# RT58X register map
Series: ARMv8-M Mainline; File version: 1.0
CPU: CM3 r0p0, little endian, MPU, no FPU, VTOR, 3 interrupt priority bits
Registers are 32-bit, read-write, reset 0x0 unless marked. A register's access mark holds for its fields unless they carry their own. Offsets are from the block's base; [hi:lo] are bit positions; {n}, {i} and the like mark numbered series; 'fields as' and 'values as' point back to an identical list; <NAME> marks a mode.

## PWM — PWM Register block
Base 0xA0C00000
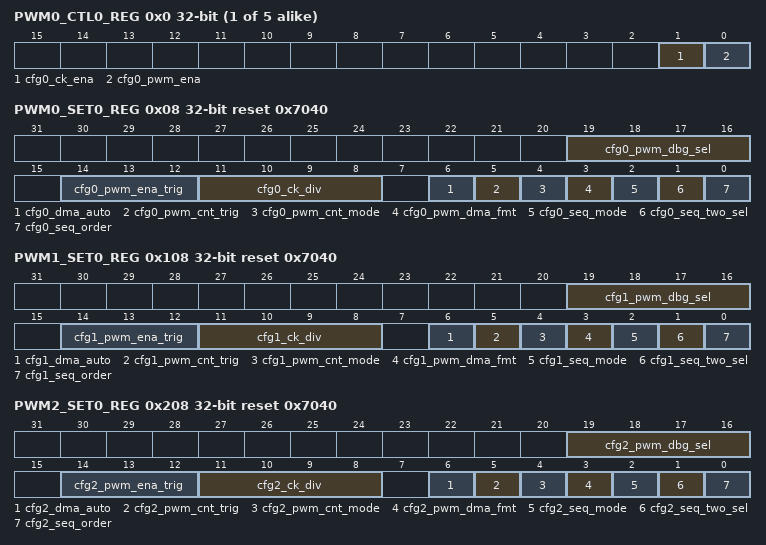
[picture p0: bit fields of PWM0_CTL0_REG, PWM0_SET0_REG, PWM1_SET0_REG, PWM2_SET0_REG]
{0x0+0x100*i} PWM{i}_CTL0_REG (i=0..4) — pwm{i} ctl0
  [1] cfg{i}_ck_ena — Enable pwm gated clock 0: disable 1: enable
    0=B_1_ITEM0 (disable); 1=B_1_ITEM1 (enable)
  [0] cfg{i}_pwm_ena — Enable pwm 0: disable 1: enable
    0=B_0_ITEM0 (disable); 1=B_0_ITEM1 (enable)
{0x4+0x100*i} PWM{i}_CTL1_REG wo (i=0..4) — pwm{i} ctl1
  [0] cfg{i}_pwm_rst — Reset pwm 1: reset
    0=B_0 (Reset pwm 1: reset)
0x08 PWM0_SET0_REG reset 0x7040 — pwm0 set0
  [19:16] cfg0_pwm_dbg_sel — Debug monitor selection
    0=B_16_to_19 (Debug monitor selection)
  [14:12] cfg0_pwm_ena_trig — PWM counter enable trigger by other PWM 0: trigger whenever PWM0 sequence finish 1: trigger whenever PWM1 sequence finish 2: trigger whenever PWM2 sequence finish 3: trigger whenever PWM3 sequence finish 4: trigger whenever PWM4 sequence finish others: self-trigger Note: if cfgX_seqx_cnt is 65535, trigger whenever PWMX 1st sequence finish where X is 0~4.
    0=B_12_to_14 (PWM counter enable trigger by other PWM 0: trigger whenever PWM0 sequence finish 1: trigger whenever PWM1 sequence finish 2: trigger whenever PWM2 sequence finish 3: trigger whenever PWM3 sequence finish 4: trigger whenever PWM4 sequence finish others: self-trigger Note: if cfgX_seqx_cnt is 65535, trigger whenever PWMX 1st sequence finish where X is 0~4.)
  [11:8] cfg0_ck_div — PWM gated clock divider value 0: clock divided by 1 1: clock divided by 2 2: clock divided by 4 3: clock divided by 8 4: clock divided by 16 5: clock divided by 32 6: clock divided by 64 7: clock divided by 128 8: clock divided by 256 otherwise: clock divided by 256
    0=B_8_to_11 (PWM gated clock divider value 0: clock divided by 1 1: clock divided by 2 2: clock divided by 4 3: clock divided by 8 4: clock divided by 16 5: clock divided by 32 6: clock divided by 64 7: clock divided by 128 8: clock divided by 256 otherwise: clock divided by 256)
  [6] cfg0_dma_auto — Auto Trigger start DMA when the amount of playback 2-sequence play does not reache cfgx_seqx_pcnt 0: No auto trigger 1: Auto trigger
    0=B_6_ITEM0 (No auto trigger); 1=B_6_ITEM1 (Auto trigger)
  [5] cfg0_pwm_cnt_trig — PWM counter trigger 0: trigger by cfg_pwm_ena 1: trigger by cfg_pwm_ena and FIFO is not empty
    0=B_5_ITEM0 (trigger by cfg_pwm_ena); 1=B_5_ITEM1 (trigger by cfg_pwm_ena and FIFO is not empty)
  [4] cfg0_pwm_cnt_mode — PWM counter mode 0: Up counter 1: Up and down counter
    0=B_4_ITEM0 (Up counter); 1=B_4_ITEM1 (Up and down counter)
  [3] cfg0_pwm_dma_fmt — PWM dma sample format 0: Format-0, 32-bit is [PHA(N), THD(N), PHA(N-1), THD(N-1)] 1: Format-1, 32-bit is [1'b0, CNT_END(N), PHA(N), THD(N)]
    0=B_3_ITEM0 (Format-0, 32-bit is [PHA(N), THD(N), PHA(N-1), THD(N-1)]); 1=B_3_ITEM1 (Format-1, 32-bit is [1'b0, CNT_END(N), PHA(N), THD(N)])
  [2] cfg0_seq_mode — PWM sequence play mode 0: non-continuous play 1: continuous play
    0=B_2_ITEM0 (non-continuous play); 1=B_2_ITEM1 (continuous play)
  [1] cfg0_seq_two_sel — Two Sequence selection 0: One sequence 1: Two sequence
    0=B_1_ITEM0 (One sequence); 1=B_1_ITEM1 (Two sequence)
  [0] cfg0_seq_order — PWM sequence play order 0: RSEQ 1st 1: TSEQ 1st
    0=B_0_ITEM0 (RSEQ 1st); 1=B_0_ITEM1 (TSEQ 1st)
{0xC+0x100*i} PWM{i}_SET1_REG (i=0..4) — pwm{i} set1
  [14:0] cfg{i}_pwm_cnt_end — PWM counter end value, ignored when cfg{i}_pwm_dma_fmt is at Format-1 value: 3…32767
0x10 PWM0_SET2_REG — pwm0 set2
  [15:0] cfg0_seqx_pcnt — Amount of sequence play 0: Play one/two sequence with 1-times (zero protection) 1: Play one/two sequence with 1-times .. 65534: Play one/two sequence with 65534-times
{0x14+0x100*i} PWM{i}_SET3_REG (i=0..4) — pwm{i} set3
  [15:0] cfg{i}_seq0_num — Number of element in RSEQ
{0x18+0x100*i} PWM{i}_SET4_REG (i=0..4) — pwm{i} set4
  [23:0] cfg{i}_seq0_rpt — Number of repeat for each element in RSEQ
{0x1C+0x100*i} PWM{i}_SET5_REG (i=0..4) — pwm{i} set5
  [23:0] cfg{i}_seq0_dly — Number of delay after RSEQ is play finish
{0x20+0x100*i} PWM{i}_SET6_REG (i=0..4) — pwm{i} set6
  [15:0] cfg{i}_seq1_num — Number of element in TSEQ
{0x24+0x100*i} PWM{i}_SET7_REG (i=0..4) — pwm{i} set7
  [23:0] cfg{i}_seq1_rpt — Number of repeat for each element in TSEQ
{0x28+0x100*i} PWM{i}_SET8_REG (i=0..4) — pwm{i} set8
  [23:0] cfg{i}_seq1_dly — Number of delay after TSEQ is play finish
{0x40+0x100*i} PWM{i}_RDMA0_CTL0_REG wo (i=0..4) — pwm{i} rdma0 ctl0
  [3:0] cfg{i}_pwm_rdma0_ctl0 — [0] Start xdma for memory access 1: enable [3:1] Reserved
    0=B_0_to_3 ([0] Start xdma for memory access 1: enable [3:1] Reserved)
{0x44+0x100*i} PWM{i}_RDMA0_CTL1_REG wo (i=0..4) — pwm{i} rdma0 ctl1
  [0] cfg{i}_pwm_rdma0_ctl1 — Software reset xdma 1: Reset
    0=B_0 (Software reset xdma 1: Reset)
{0x48+0x100*i} PWM{i}_RDMA0_SET0_REG (i=0..4) — [15:0] Segment size, 4-byte aligned 0: Illegal value Others: 1…65535 (Block size < Segment size) [31:16] Block size, 4-byte aligned 0: Single-shot mode Others: 1…65535 (Block size < Segment size)
{0x4C+0x100*i} PWM{i}_RDMA0_SET1_REG (i=0..4) — start address point, 4-byte aligned The 2-LSB bit will be ignored
{0x50+0x100*i} PWM{i}_RDMA0_SET2_REG (i=0..4) — pwm{i} rdma0 set2
  [7:0] cfg{i}_pwm_rdma0_set2 — [0] Set initial address 0: when xdma start, initial address is loaded from ptr 1: when xdma reset, initial address is loaded from ptr [3:1] Reserved [5:4] DMA data format 0: word, 4-bytes aligned 1: halfword, 2-bytes aligned 2/3: 1-byte aligned [7:6] Reserved
    0=B_0_to_7 ([0] Set initial address 0: when xdma start, initial address is loaded from ptr 1: when xdma reset, initial address is loaded from ptr [3:1] Reserved [5:4] DMA data format 0: word, 4-bytes aligned 1: halfword, 2-bytes aligned 2/3: 1-byte aligned [7:6] Reserved)
{0x58+0x100*i} PWM{i}_RDMA0_R0_REG ro (i=0..4) — Status of xdma next pointer address
{0x5C+0x100*i} PWM{i}_RDMA0_R1_REG ro (i=0..4) — [0] xdma interrupt status [1] xdma error interrupt status [2] OR(xdma interrupt status, xdma error interrupt status) [9:8] xdma counter status, used for ping-pong buffer to check buffer status [16] xdma enable [17] xdma_done [19:18] xdma_status
{0x60+0x100*i} PWM{i}_RDMA1_CTL0_REG wo (i=0..4) — pwm{i} rdma1 ctl0
  [3:0] cfg{i}_pwm_rdma1_ctl0 — [0] Start xdma for memory access 1: enable [3:1] Reserved
    values as PWM0_RDMA0_CTL0_REG.cfg{i}_pwm_rdma0_ctl0
{0x64+0x100*i} PWM{i}_RDMA1_CTL1_REG wo (i=0..4) — pwm{i} rdma1 ctl1
  [0] cfg{i}_pwm_rdma1_ctl1 — Software reset xdma 1: Reset
    0=B_0 (Software reset xdma 1: Reset)
{0x68+0x100*i} PWM{i}_RDMA1_SET0_REG (i=0..4) — [15:0] Segment size, 4-byte aligned 0: Illegal value Others: 1…65535 (Block size < Segment size) [31:16] Block size, 4-byte aligned 0: Single-shot mode Others: 1…65535 (Block size < Segment size)
{0x6C+0x100*i} PWM{i}_RDMA1_SET1_REG (i=0..4) — start address point, 4-byte aligned The 2-LSB bit will be ignored
{0x70+0x100*i} PWM{i}_RDMA1_SET2_REG (i=0..4) — pwm{i} rdma1 set2
  [7:0] cfg{i}_pwm_rdma1_set2 — [0] Set initial address 0: when xdma start, initial address is loaded from ptr 1: when xdma reset, initial address is loaded from ptr [3:1] Reserved [5:4] DMA data format 0: word, 4-bytes aligned 1: halfword, 2-bytes aligned 2/3: 1-byte aligned [7:6] Reserved
    values as PWM0_RDMA0_SET2_REG.cfg{i}_pwm_rdma0_set2
{0x78+0x100*i} PWM{i}_RDMA1_R0_REG ro (i=0..4) — Status of xdma next pointer address
{0x7C+0x100*i} PWM{i}_RDMA1_R1_REG ro (i=0..4) — [0] xdma interrupt status [1] xdma error interrupt status [2] OR(xdma interrupt status, xdma error interrupt status) [9:8] xdma counter status, used for ping-pong buffer to check buffer status [16] xdma enable [17] xdma_done [19:18] xdma_status
{0xA0+0x100*i} PWM{i}_INT_CLEAR_REG wo (i=0..3) — pwm{i} int clear
  [6:0] cfg{i}_pwm_int_clear — [0] Clear RDMA0 interrpt; 1: clear [1] Clear RDMA0 error interrupt; 1: clear [2] Clear RDMA1 interrpt; 1: clear [3] Clear RDMA1 error interrupt; 1: clear [4] Clear RSEQ done interrupt; 1: clear [5] Clear TSEQ done interrupt; 1: clear [6] Clear one/two sequence*cfgx_seqx_pcnt done interrupt; 1: clear
    0=B_0_to_6 ([0] Clear RDMA0 interrpt; 1: clear [1] Clear RDMA0 error interrupt; 1: clear [2] Clear RDMA1 interrpt; 1: clear [3] Clear RDMA1 error interrupt; 1: clear [4] Clear RSEQ done interrupt; 1: clear [5] Clear TSEQ done interrupt; 1: clear [6] Clear one/two sequence*cfgx_seqx_pcnt done interrupt; 1: clear)
{0xA4+0x100*i} PWM{i}_INT_MASK_REG reset 0x70 (i=0..3) — pwm{i} int mask
  [6:0] cfg{i}_pwm_int_mask — [0] Mask RDMA0 interrpt; 0: No mask 1: Mask [1] Mask RDMA0 error interrupt; 0: No mask 1: Mask [2] Mask RDMA1 interrpt; 0: No mask 1: Mask [3] Mask RDMA1 error interrupt; 0: No mask 1: Mask [4] Mask RSEQ done interrupt; 0: No mask 1: Mask [5] Mask TSEQ done interrupt; 0: No mask 1: Mask [6] Mask one/two sequence*cfgx_seqx_pcnt done interrupt;0: No mask 1: Mask
    0=B_0_to_6 ([0] Mask RDMA0 interrpt; 0: No mask 1: Mask [1] Mask RDMA0 error interrupt; 0: No mask 1: Mask [2] Mask RDMA1 interrpt; 0: No mask 1: Mask [3] Mask RDMA1 error interrupt; 0: No mask 1: Mask [4] Mask RSEQ done interrupt; 0: No mask 1: Mask [5] Mask TSEQ done interrupt; 0: No mask 1: Mask [6] Mask one/two sequence*cfgx_seqx_pcnt done interrupt;0: No mask 1: Mask)
0xA8 PWM0_INT_STATUS_REG ro — pwm0 int status
  [6:0] cfg0_pwm_int_status — [0] Status of RDMA0 interrupt [1] Status of RDMA0 error interrupt [2] Status of RDMA1 interrupt [3] Status of RDMA1 error interrupt [4] Status of RSEQ done interrupt; [5] Status of TSEQ done interrupt; [6] Status of one/two sequence*cfgx_seqx_pcnt done interrupt;
    0=B_0_to_6 ([0] Status of RDMA0 interrupt [1] Status of RDMA0 error interrupt [2] Status of RDMA1 interrupt [3] Status of RDMA1 error interrupt [4] Status of RSEQ done interrupt; [5] Status of TSEQ done interrupt; [6] Status of one/two sequence*cfgx_seqx_pcnt done interrupt;)
0x108 PWM1_SET0_REG reset 0x7040 — pwm1 set0
  [19:16] cfg1_pwm_dbg_sel — Debug monitor selection
    0=B_16_to_19 (Debug monitor selection)
  [14:12] cfg1_pwm_ena_trig — PWM counter enable trigger by other PWM 0: trigger whenever PWM0 sequence finish 1: trigger whenever PWM1 sequence finish 2: trigger whenever PWM2 sequence finish 3: trigger whenever PWM3 sequence finish 4: trigger whenever PWM4 sequence finish others: self-trigger Note: if cfgX_seqx_cnt is 65535, trigger whenever PWMX 1st sequence finish where X is 0~4.
    values as PWM0_SET0_REG.cfg0_pwm_ena_trig
  [11:8] cfg1_ck_div — PWM gated clock divider value 0: clock divided by 1 1: clock divided by 2 2: clock divided by 4 3: clock divided by 8 4: clock divided by 16 5: clock divided by 32 6: clock divided by 64 7: clock divided by 128 8: clock divided by 256 otherwise: clock divided by 256
    values as PWM0_SET0_REG.cfg0_ck_div
  [6] cfg1_dma_auto — Auto Trigger start DMA when the amount of playback 2-sequence play does not reache cfgx_seqx_pcnt 0: No auto trigger 1: Auto trigger
    0=B_6_ITEM0 (No auto trigger); 1=B_6_ITEM1 (Auto trigger)
  [5] cfg1_pwm_cnt_trig — PWM counter trigger 0: trigger by cfg_pwm_ena 1: trigger by cfg_pwm_ena and FIFO is not empty
    values as PWM0_SET0_REG.cfg0_pwm_cnt_trig
  [4] cfg1_pwm_cnt_mode — PWM counter mode 0: Up counter 1: Up and down counter
    0=B_4_ITEM0 (Up counter); 1=B_4_ITEM1 (Up and down counter)
  [3] cfg1_pwm_dma_fmt — PWM dma sample format 0: Format-0, 32-bit is [PHA(N), THD(N), PHA(N-1), THD(N-1)] 1: Format-1, 32-bit is [1'b0, CNT_END(N), PHA(N), THD(N)]
    values as PWM0_SET0_REG.cfg0_pwm_dma_fmt
  [2] cfg1_seq_mode — PWM sequence play mode 0: non-continuous play 1: continuous play
    values as PWM0_SET0_REG.cfg0_seq_mode
  [1] cfg1_seq_two_sel — Two Sequence selection 0: One sequence 1: Two sequence
    0=B_1_ITEM0 (One sequence); 1=B_1_ITEM1 (Two sequence)
  [0] cfg1_seq_order — PWM sequence play order 0: RSEQ 1st 1: TSEQ 1st
    0=B_0_ITEM0 (RSEQ 1st); 1=B_0_ITEM1 (TSEQ 1st)
{0x10+0x100*i} PWM{i}_SET2_REG (i=1..4) — pwm{i} set2
  [15:0] cfg{i}_seqx_pcnt — Amount of sequence play 0: Play one/two sequence with 1-times N: Play one/two sequence with N-times 65535: Play one/two sequence infinitely
0x1A8 PWM1_INT_STATUS_REG ro — pwm1 int status
  [6:0] cfg1_pwm_int_status — [0] Status of RDMA0 interrupt [1] Status of RDMA0 error interrupt [2] Status of RDMA1 interrupt [3] Status of RDMA1 error interrupt [4] Status of RSEQ done interrupt [5] Status of TSEQ done interrupt [6] Status of one/two sequence*cfgx_seqx_pcnt done interrupt
    0=B_0_to_6 ([0] Status of RDMA0 interrupt [1] Status of RDMA0 error interrupt [2] Status of RDMA1 interrupt [3] Status of RDMA1 error interrupt [4] Status of RSEQ done interrupt [5] Status of TSEQ done interrupt [6] Status of one/two sequence*cfgx_seqx_pcnt done interrupt)
0x208 PWM2_SET0_REG reset 0x7040 — pwm2 set0
  [19:16] cfg2_pwm_dbg_sel — Debug monitor selection
    0=B_16_to_19 (Debug monitor selection)
  [14:12] cfg2_pwm_ena_trig — PWM counter enable trigger by other PWM 0: trigger whenever PWM0 sequence finish 1: trigger whenever PWM1 sequence finish 2: trigger whenever PWM2 sequence finish 3: trigger whenever PWM3 sequence finish 4: trigger whenever PWM4 sequence finish others: self-trigger Note: if cfgX_seqx_cnt is 65535, trigger whenever PWMX 1st sequence finish where X is 0~4.
    values as PWM0_SET0_REG.cfg0_pwm_ena_trig
  [11:8] cfg2_ck_div — PWM gated clock divider value 0: clock divided by 1 1: clock divided by 2 2: clock divided by 4 3: clock divided by 8 4: clock divided by 16 5: clock divided by 32 6: clock divided by 64 7: clock divided by 128 8: clock divided by 256 otherwise: clock divided by 256
    values as PWM0_SET0_REG.cfg0_ck_div
  [6] cfg2_dma_auto — Auto Trigger start DMA when the amount of playback 2-sequence play does not reache cfgx_seqx_pcnt 0: No auto trigger 1: Auto trigger
    0=B_6_ITEM0 (No auto trigger); 1=B_6_ITEM1 (Auto trigger)
  [5] cfg2_pwm_cnt_trig — PWM counter trigger 0: trigger by cfg2_pwm_ena 1: trigger by cfg2_pwm_ena and FIFO is not empty
    0=B_5_ITEM0 (trigger by cfg2_pwm_ena); 1=B_5_ITEM1 (trigger by cfg2_pwm_ena and FIFO is not empty)
  [4] cfg2_pwm_cnt_mode — PWM counter mode 0: Up counter 1: Up and down counter
    0=B_4_ITEM0 (Up counter); 1=B_4_ITEM1 (Up and down counter)
  [3] cfg2_pwm_dma_fmt — PWM dma sample format 0: Format-0, 32-bit is [PHA(N), THD(N), PHA(N-1), THD(N-1)] 1: Format-1, 32-bit is [1'b0, CNT_END(N), PHA(N), THD(N)]
    values as PWM0_SET0_REG.cfg0_pwm_dma_fmt
  [2] cfg2_seq_mode — PWM sequence play mode 0: non-continuous play 1: continuous play
    values as PWM0_SET0_REG.cfg0_seq_mode
  [1] cfg2_seq_two_sel — Two Sequence selection 0: One sequence 1: Two sequence
    0=B_1_ITEM0 (One sequence); 1=B_1_ITEM1 (Two sequence)
  [0] cfg2_seq_order — PWM sequence play order 0: RSEQ 1st 1: TSEQ 1st
    0=B_0_ITEM0 (RSEQ 1st); 1=B_0_ITEM1 (TSEQ 1st)
{0xA8+0x100*i} PWM{i}_INT_STATUS_REG ro (i=2..4) — pwm{i} int status
  [6:0] cfg{i}_pwm_int_status — [0] Status of RDMA0 interrupt [1] Status of RDMA0 error interrupt [2] Status of RDMA1 interrupt [3] Status of RDMA1 error interrupt [4] Status of RSEQ done interrupt; [5] Status of TSEQ done interrupt; [6] Status of one/two sequence*cfgx_seqx_pcnt done interrupt;
    values as PWM0_INT_STATUS_REG.cfg0_pwm_int_status
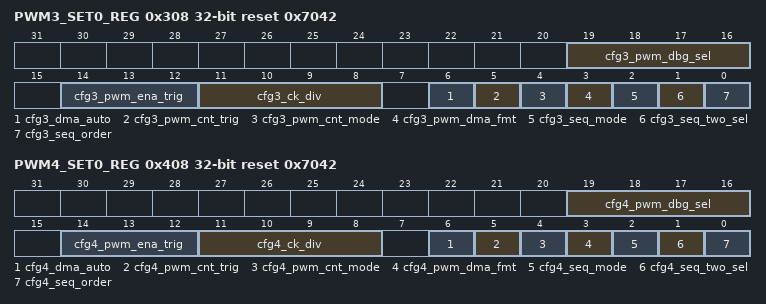
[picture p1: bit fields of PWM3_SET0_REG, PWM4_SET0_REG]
0x308 PWM3_SET0_REG reset 0x7042 — pwm3 set0
  [19:16] cfg3_pwm_dbg_sel — Debug monitor selection
    0=B_16_to_19 (Debug monitor selection)
  [14:12] cfg3_pwm_ena_trig — PWM counter enable trigger by other PWM 0: trigger whenever PWM0 sequence finish 1: trigger whenever PWM1 sequence finish 2: trigger whenever PWM2 sequence finish 3: trigger whenever PWM3 sequence finish 4: trigger whenever PWM4 sequence finish others: self-trigger Note: if cfgX_seqx_cnt is 65535, trigger whenever PWMX 1st sequence finish where X is 0~4.
    values as PWM0_SET0_REG.cfg0_pwm_ena_trig
  [11:8] cfg3_ck_div — PWM gated clock divider value 0: clock divided by 1 1: clock divided by 2 2: clock divided by 4 3: clock divided by 8 4: clock divided by 16 5: clock divided by 32 6: clock divided by 64 7: clock divided by 128 8: clock divided by 256 otherwise: clock divided by 256
    values as PWM0_SET0_REG.cfg0_ck_div
  [6] cfg3_dma_auto — Auto Trigger start DMA when the amount of playback 2-sequence play does not reache cfgx_seqx_pcnt 0: No auto trigger 1: Auto trigger
    0=B_6_ITEM0 (No auto trigger); 1=B_6_ITEM1 (Auto trigger)
  [5] cfg3_pwm_cnt_trig — PWM counter trigger 0: trigger by cfg_pwm_ena 1: trigger by cfg_pwm_ena and FIFO is not empty
    values as PWM0_SET0_REG.cfg0_pwm_cnt_trig
  [4] cfg3_pwm_cnt_mode — PWM counter mode 0: Up counter 1: Up and down counter
    0=B_4_ITEM0 (Up counter); 1=B_4_ITEM1 (Up and down counter)
  [3] cfg3_pwm_dma_fmt — PWM dma sample format 0: Format-0, 32-bit is [PHA(N), THD(N), PHA(N-1), THD(N-1)] 1: Format-1, 32-bit is [1'b0, CNT_END(N), PHA(N), THD(N)]
    values as PWM0_SET0_REG.cfg0_pwm_dma_fmt
  [2] cfg3_seq_mode — PWM sequence play mode 0: non-continuous play 1: continuous play
    values as PWM0_SET0_REG.cfg0_seq_mode
  [1] cfg3_seq_two_sel — Two Sequence selection 0: One sequence 1: Two sequence
    0=B_1_ITEM0 (One sequence); 1=B_1_ITEM1 (Two sequence)
  [0] cfg3_seq_order — PWM sequence play order 0: RSEQ 1st 1: TSEQ 1st
    0=B_0_ITEM0 (RSEQ 1st); 1=B_0_ITEM1 (TSEQ 1st)
0x408 PWM4_SET0_REG reset 0x7042 — pwm4 set0
  [19:16] cfg4_pwm_dbg_sel — Debug monitor selection
    0=B_16_to_19 (Debug monitor selection)
  [14:12] cfg4_pwm_ena_trig — PWM counter enable trigger by other PWM 0: trigger whenever PWM0 sequence finish 1: trigger whenever PWM1 sequence finish 2: trigger whenever PWM2 sequence finish 3: trigger whenever PWM3 sequence finish 4: trigger whenever PWM4 sequence finish others: self-trigger Note: if cfgX_seqx_cnt is 65535, trigger whenever PWMX 1st sequence finish where X is 0~4.
    values as PWM0_SET0_REG.cfg0_pwm_ena_trig
  [11:8] cfg4_ck_div — PWM gated clock divider value 0: clock divided by 1 1: clock divided by 2 2: clock divided by 4 3: clock divided by 8 4: clock divided by 16 5: clock divided by 32 6: clock divided by 64 7: clock divided by 128 8: clock divided by 256 otherwise: clock divided by 256
    values as PWM0_SET0_REG.cfg0_ck_div
  [6] cfg4_dma_auto — Auto Trigger start DMA when the amount of playback 2-sequence play does not reache cfgx_seqx_pcnt 0: No auto trigger 1: Auto trigger
    0=B_6_ITEM0 (No auto trigger); 1=B_6_ITEM1 (Auto trigger)
  [5] cfg4_pwm_cnt_trig — PWM counter trigger 0: trigger by cfg_pwm_ena 1: trigger by cfg_pwm_ena and FIFO is not empty
    values as PWM0_SET0_REG.cfg0_pwm_cnt_trig
  [4] cfg4_pwm_cnt_mode — PWM counter mode 0: Up counter 1: Up and down counter
    0=B_4_ITEM0 (Up counter); 1=B_4_ITEM1 (Up and down counter)
  [3] cfg4_pwm_dma_fmt — PWM dma sample format 0: Format-0, 32-bit is [PHA(N), THD(N), PHA(N-1), THD(N-1)] 1: Format-1, 32-bit is [1'b0, CNT_END(N), PHA(N), THD(N)]
    values as PWM0_SET0_REG.cfg0_pwm_dma_fmt
  [2] cfg4_seq_mode — PWM sequence play mode 0: non-continuous play 1: continuous play
    values as PWM0_SET0_REG.cfg0_seq_mode
  [1] cfg4_seq_two_sel — Two Sequence selection 0: One sequence 1: Two sequence
    0=B_1_ITEM0 (One sequence); 1=B_1_ITEM1 (Two sequence)
  [0] cfg4_seq_order — PWM sequence play order 0: RSEQ 1st 1: TSEQ 1st
    0=B_0_ITEM0 (RSEQ 1st); 1=B_0_ITEM1 (TSEQ 1st)
0x4A0 PWM4_INT_CLEAR_REG wo — pwm4 int clear
  [6:0] cfg4_pwm_int_clear — [0] Clear RDMA0 interrpt; 1: clear [1] Clear RDMA0 error interrupt; 1: clear [2] Clear RDMA1 interrpt; 1: clear [3] Clear RDMA1 error interrupt; 1: clear [4] Clear RSEQ done interrupt; 1: clear [5] Clear TSEQ done interrupt; 1: clear [6] Clear one/two sequence*cfgx_seqx_pcnt interrupt; 1: clear
    0=B_0_to_6 ([0] Clear RDMA0 interrpt; 1: clear [1] Clear RDMA0 error interrupt; 1: clear [2] Clear RDMA1 interrpt; 1: clear [3] Clear RDMA1 error interrupt; 1: clear [4] Clear RSEQ done interrupt; 1: clear [5] Clear TSEQ done interrupt; 1: clear [6] Clear one/two sequence*cfgx_seqx_pcnt interrupt; 1: clear)
0x4A4 PWM4_INT_MASK_REG reset 0x70 — pwm4 int mask
  [6:0] cfg4_pwm_int_mask — [0] Mask RDMA0 interrpt; 0: No mask 1: Mask [1] Mask RDMA0 error interrupt; 0: No mask 1: Mask [2] Mask RDMA1 interrpt; 0: No mask 1: Mask [3] Mask RDMA1 error interrupt; 0: No mask 1: Mask [4] Mask RSEQ done interrupt; 0: No mask 1: Mask [5] Mask TSEQ done interrupt; 0: No mask 1: Mask [6] Mask one/two sequence*cfgx_seqx_pcnt interrupt;0: No mask 1: Mask
    0=B_0_to_6 ([0] Mask RDMA0 interrpt; 0: No mask 1: Mask [1] Mask RDMA0 error interrupt; 0: No mask 1: Mask [2] Mask RDMA1 interrpt; 0: No mask 1: Mask [3] Mask RDMA1 error interrupt; 0: No mask 1: Mask [4] Mask RSEQ done interrupt; 0: No mask 1: Mask [5] Mask TSEQ done interrupt; 0: No mask 1: Mask [6] Mask one/two sequence*cfgx_seqx_pcnt interrupt;0: No mask 1: Mask)
